# STM32H503xx register map
File version: 1.0
Registers are 32-bit, read-write, reset 0x0 unless marked. A register's access mark holds for its fields unless they carry their own. Offsets are from the block's base; [hi:lo] are bit positions; {n}, {i} and the like mark numbered series; 'fields as' and 'values as' point back to an identical list.

## RCC — Reset and Clock Control
Base 0x44020C00
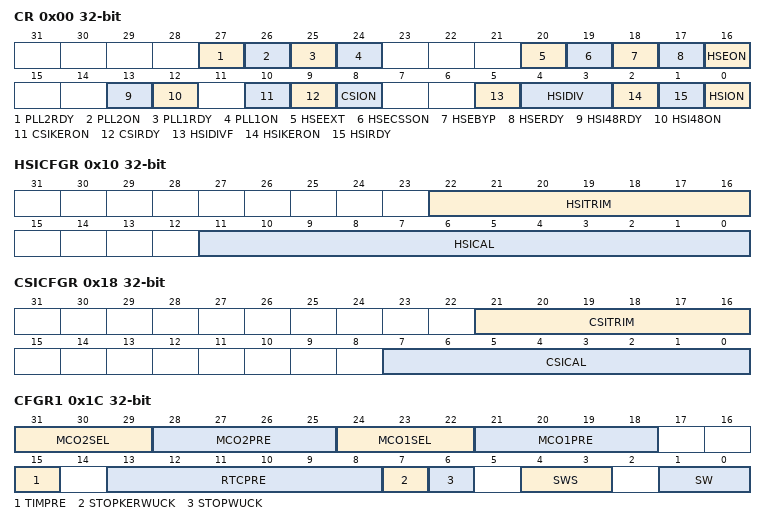
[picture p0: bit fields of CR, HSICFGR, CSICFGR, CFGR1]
0x00 CR — RCC clock control register
  [27] PLL2RDY — PLL2 ready
  [26] PLL2ON — PLL2 enable
  [25] PLL1RDY — System PLL clock ready
  [24] PLL1ON — System PLL clock enable
  [20] HSEEXT — External High Speed clock type in Bypass mode
    0=ANALOG_TYPE (ANALOG clock used as HSE external clock source); 1=DIGITAL_TYPE (DIGITAL clock used as HSE external clock source)
  [19] HSECSSON — HSE Clock Security System enable
  [18] HSEBYP — External High Speed oscillator (HSE) clock bypass
  [17] HSERDY — External High Speed oscillator (HSE) clock ready
  [16] HSEON — External High Speed oscillator (HSE) clock enable
  [13] HSI48RDY — HSI48 clock ready
  [12] HSI48ON — HSI48 clock enable
  [10] CSIKERON — The Internal RC 4MHz oscillator (CSI) clock enable for some IPs Kernel
  [9] CSIRDY — The Internal RC 4MHz oscillator (CSI) clock ready
  [8] CSION — The Internal RC 4MHz oscillator (CSI) clock enable
  [5] HSIDIVF — HSI Divider flag
  [4:3] HSIDIV — Internal High Speed clock divider selection
    0=DIV_1 (HSI_DIV1 clock activation); 1=DIV_2 (HSI_DIV2 clock activation); 2=DIV_4 (HSI_DIV4 clock activation); 3=DIV_8 (HSI_DIV8 clock activation)
  [2] HSIKERON — Internal High Speed oscillator (HSI) clock enable for some IPs Kernel
  [1] HSIRDY — Internal High Speed oscillator (HSI) clock ready flag
  [0] HSION — Internal High Speed oscillator (HSI) clock enable
0x10 HSICFGR — RCC HSI Clock Calibration Register
  [22:16] HSITRIM — HSITRIM[6:0] bits
  [11:0] HSICAL — HSICAL[11:0] bits
0x14 CRRCR — RCC Clock Recovery RC Register
  [9:0] HSI48CAL — HSI48CAL[8:0] bits
0x18 CSICFGR — RCC CSI Clock Calibration Register
  [21:16] CSITRIM — CSITRIM[5:0] bits
  [7:0] CSICAL — CSICAL[7:0] bits
0x1C CFGR1 — RCC clock configuration register 1
  [31:29] MCO2SEL
  [28:25] MCO2PRE
  [24:22] MCO1SEL
  [21:18] MCO1PRE
  [15] TIMPRE
    0=TWICE; 1=FOUR_TIMES
  [13:8] RTCPRE — HSE division factor for RTC Clock
    0=NOCLOCK; {v}=DIV_{v} (v=2..63)
  [7] STOPKERWUCK — Kernel Clock Selection after a Wake Up from STOP
    0=HSI (HSI selection as kernel clock after wake-up from STOP); 1=CSI (CSI selection as kernel clock after wake-up from STOP)
  [6] STOPWUCK — Wake Up from stop and HSE CSS backup clock selection
    0=HSI (HSI selection as system clock after wake-up from STOP); 1=CSI (CSI selection as system clock after wake-up from STOP)
  [4:3] SWS — SWS[1:0] bits (System Clock Switch Status)
    0=HSI (HSI oscillator used as system clock); 1=CSI (CSI oscillator used as system clock); 2=HSE (HSE oscillator used as system clock); 3=PLL1 (PLL1 used as system clock)
  [1:0] SW — SW[1:0] bits (System clock Switch)
    0=HSI (HSI oscillator selection as system clock); 1=CSI (CSI oscillator selection as system clock); 2=HSE (HSE oscillator selection as system clock); 3=PLL1 (PLL1 selection as system clock)
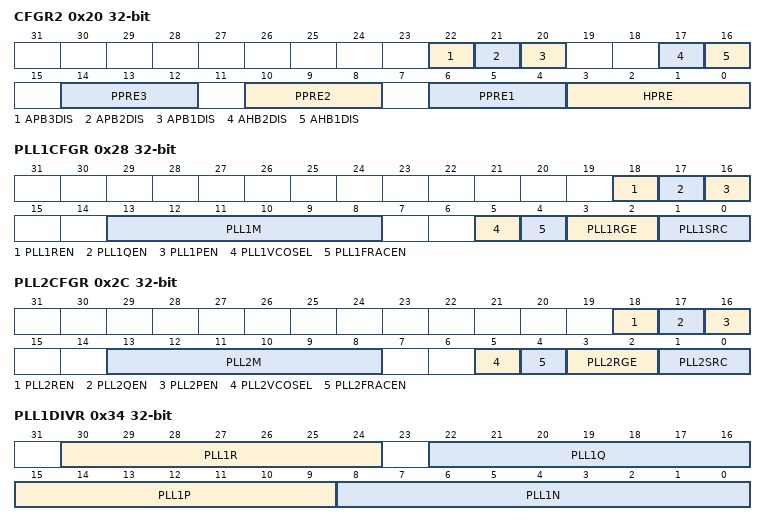
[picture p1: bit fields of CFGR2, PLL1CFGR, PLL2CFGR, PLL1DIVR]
0x20 CFGR2 — RCC clock configuration register 2
  [22] APB3DIS — APB3 clock disable
  [21] APB2DIS — APB2 clock disable
  [20] APB1DIS — APB1 clock disable
  [17] AHB2DIS — AHB2 clock disable
  [16] AHB1DIS — AHB1 clock disable
  [14:12] PPRE3 — PPRE3[2:0] bits (APB3 prescaler)
    0=DIV_1 (HCLK not divided); 4=DIV_2 (HCLK divided by 2); 5=DIV_4 (HCLK divided by 4); 6=DIV_8 (HCLK divided by 8); 7=DIV_16 (HCLK divided by 16)
  [10:8] PPRE2 — PPRE2[2:0] bits (APB2 prescaler)
    values as PPRE3
  [6:4] PPRE1 — PPRE1[2:0] bits (APB1 prescaler)
    values as PPRE3
  [3:0] HPRE — HPRE[3:0] bits (AHB prescaler)
    0=DIV_1 (SYSCLK not divided); 8=DIV_2 (SYSCLK divided by 2); 9=DIV_4 (SYSCLK divided by 4); 10=DIV_8 (SYSCLK divided by 8); 11=DIV_16 (SYSCLK divided by 16); 12=DIV_64 (SYSCLK divided by 64); 13=DIV_128 (SYSCLK divided by 128); 14=DIV_256 (SYSCLK divided by 256); 15=DIV_512 (SYSCLK divided by 512)
0x28 PLL1CFGR — RCC PLL1 Configuration Register
  [18] PLL1REN
  [17] PLL1QEN
  [16] PLL1PEN
  [13:8] PLL1M
  [5] PLL1VCOSEL
  [4] PLL1FRACEN
  [3:2] PLL1RGE
  [1:0] PLL1SRC
    0=NONE (No clock selected as main PLL1 entry clock source); 1=HSI (HSI clock selected as main PLL1 entry clock source); 2=CSI (CSI clock selected as main PLL1 entry clock source); 3=HSE (HSE clock selected as main PLL1 entry clock source)
0x2C PLL2CFGR — RCC PLL2 Configuration Register
  [18] PLL2REN
  [17] PLL2QEN
  [16] PLL2PEN
  [13:8] PLL2M
  [5] PLL2VCOSEL
  [4] PLL2FRACEN
  [3:2] PLL2RGE
  [1:0] PLL2SRC
    0=NONE (No clock selected as main PLL2 entry clock source); 2=CSI (CSI clock selected as main PLL2 entry clock source); 1=HSI (HSI clock selected as main PLL2 entry clock source); 3=HSE (HSE clock selected as main PLL2 entry clock source)
0x34 PLL1DIVR — RCC PLL1 Dividers Configuration Register
  [30:24] PLL1R, [22:16] PLL1Q, [15:9] PLL1P, [8:0] PLL1N
0x38 PLL1FRACR — RCC PLL1 Fractional Divider Configuration Register
  [15:3] PLL1FRACN
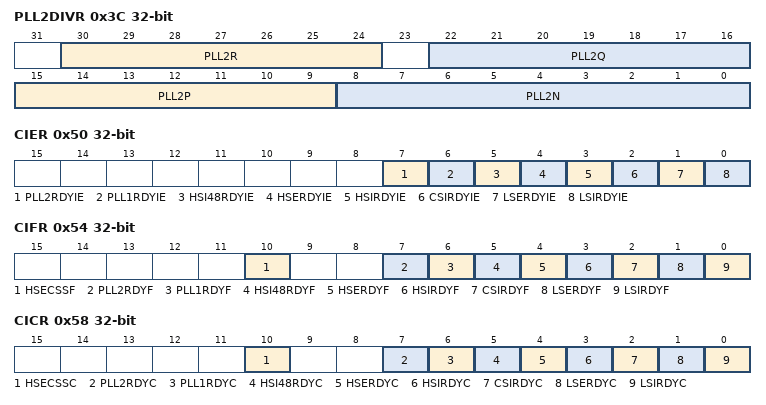
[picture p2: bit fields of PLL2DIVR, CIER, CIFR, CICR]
0x3C PLL2DIVR — RCC PLL2 Dividers Configuration Register
  [30:24] PLL2R, [22:16] PLL2Q, [15:9] PLL2P, [8:0] PLL2N
0x40 PLL2FRACR — RCC PLL2 Fractional Divider Configuration Register
  [15:3] PLL2FRACN
0x50 CIER — RCC Clock Interrupt Enable Register
  [7] PLL2RDYIE, [6] PLL1RDYIE, [5] HSI48RDYIE, [4] HSERDYIE, [3] HSIRDYIE, [2] CSIRDYIE, [1] LSERDYIE, [0] LSIRDYIE
0x54 CIFR — RCC Clock Interrupt Flag Register
  [10] HSECSSF, [7] PLL2RDYF, [6] PLL1RDYF, [5] HSI48RDYF, [4] HSERDYF, [3] HSIRDYF, [2] CSIRDYF, [1] LSERDYF, [0] LSIRDYF
0x58 CICR — RCC Clock Interrupt Clear Register
  [10] HSECSSC, [7] PLL2RDYC, [6] PLL1RDYC, [5] HSI48RDYC, [4] HSERDYC, [3] HSIRDYC, [2] CSIRDYC, [1] LSERDYC, [0] LSIRDYC
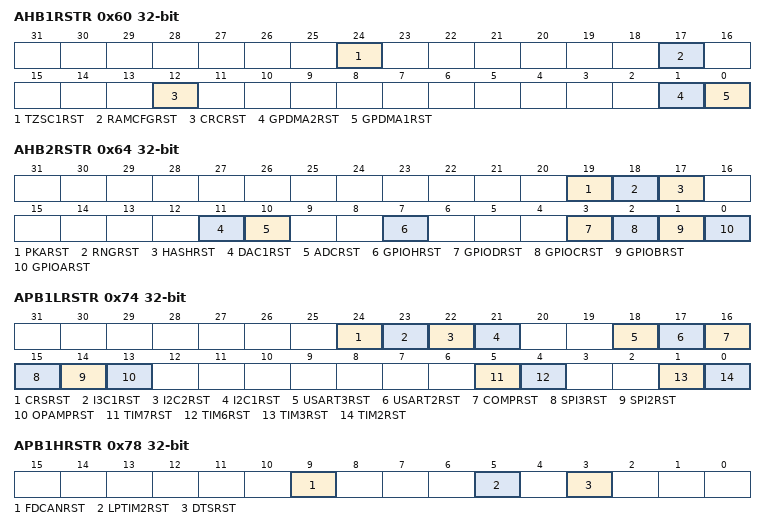
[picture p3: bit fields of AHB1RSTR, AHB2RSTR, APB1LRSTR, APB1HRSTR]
0x60 AHB1RSTR — RCC AHB1 Peripherals Reset Register
  [24] TZSC1RST, [17] RAMCFGRST, [12] CRCRST, [1] GPDMA2RST, [0] GPDMA1RST
0x64 AHB2RSTR — RCC AHB2 Peripherals Reset Register
  [19] PKARST, [18] RNGRST, [17] HASHRST, [11] DAC1RST, [10] ADCRST, [7] GPIOHRST, [3] GPIODRST, [2] GPIOCRST, [1] GPIOBRST, [0] GPIOARST
0x74 APB1LRSTR — RCC APB1 Peripherals reset Low Word register
  [24] CRSRST, [23] I3C1RST, [22] I2C2RST, [21] I2C1RST, [18] USART3RST, [17] USART2RST, [16] COMPRST, [15] SPI3RST, [14] SPI2RST, [13] OPAMPRST, [5] TIM7RST, [4] TIM6RST, [1] TIM3RST, [0] TIM2RST
0x78 APB1HRSTR — RCC APB1 Peripherals reset High Word register
  [9] FDCANRST, [5] LPTIM2RST, [3] DTSRST
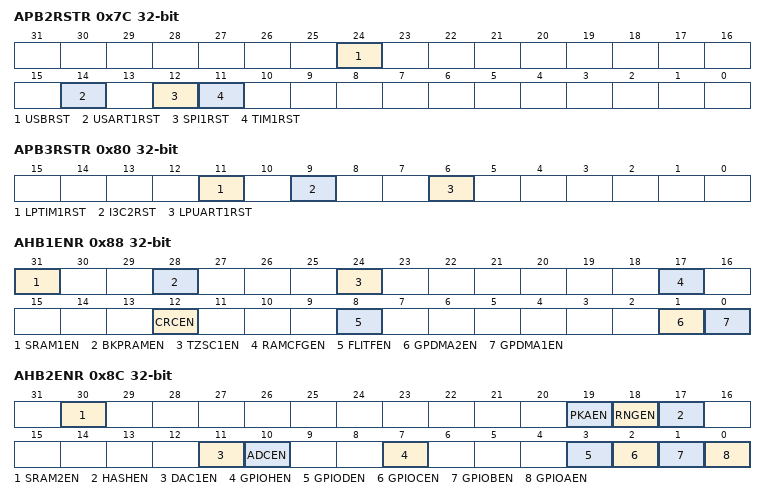
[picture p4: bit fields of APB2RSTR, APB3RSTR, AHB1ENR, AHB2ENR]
0x7C APB2RSTR — RCC APB2 Peripherals Reset Register
  [24] USBRST, [14] USART1RST, [12] SPI1RST, [11] TIM1RST
0x80 APB3RSTR — RCC APB3 Peripherals Reset Register
  [11] LPTIM1RST, [9] I3C2RST, [6] LPUART1RST
0x88 AHB1ENR — RCC AHB1 Peripherals Clock Enable Register
  [31] SRAM1EN, [28] BKPRAMEN, [24] TZSC1EN, [17] RAMCFGEN, [12] CRCEN, [8] FLITFEN, [1] GPDMA2EN, [0] GPDMA1EN
0x8C AHB2ENR — RCC AHB2 Peripherals Clock Enable Register
  [30] SRAM2EN, [19] PKAEN, [18] RNGEN, [17] HASHEN, [11] DAC1EN, [10] ADCEN, [7] GPIOHEN, [3] GPIODEN, [2] GPIOCEN, [1] GPIOBEN, [0] GPIOAEN
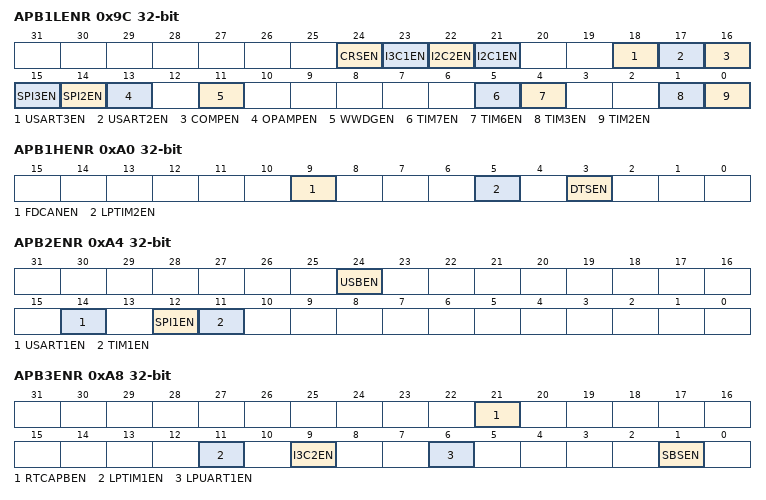
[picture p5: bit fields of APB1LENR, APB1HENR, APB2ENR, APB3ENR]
0x9C APB1LENR — RCC APB1 Peripherals clock Enable Low Word register
  [24] CRSEN, [23] I3C1EN, [22] I2C2EN, [21] I2C1EN, [18] USART3EN, [17] USART2EN, [16] COMPEN, [15] SPI3EN, [14] SPI2EN, [13] OPAMPEN, [11] WWDGEN, [5] TIM7EN, [4] TIM6EN, [1] TIM3EN, [0] TIM2EN
0xA0 APB1HENR — RCC APB1 Peripherals clock Enable High Word register
  [9] FDCANEN, [5] LPTIM2EN, [3] DTSEN
0xA4 APB2ENR — RCC APB2 Peripherals Clock Enable Register
  [24] USBEN, [14] USART1EN, [12] SPI1EN, [11] TIM1EN
0xA8 APB3ENR — RCC APB3 Peripherals Clock Enable Register
  [21] RTCAPBEN, [11] LPTIM1EN, [9] I3C2EN, [6] LPUART1EN, [1] SBSEN
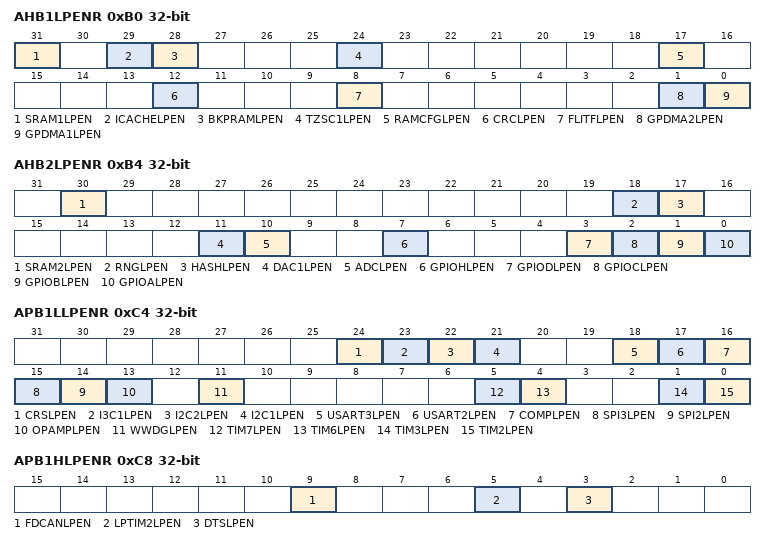
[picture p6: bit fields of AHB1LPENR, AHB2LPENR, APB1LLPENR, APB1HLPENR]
0xB0 AHB1LPENR — RCC AHB1 Peripheral sleep clock Register
  [31] SRAM1LPEN, [29] ICACHELPEN, [28] BKPRAMLPEN, [24] TZSC1LPEN, [17] RAMCFGLPEN, [12] CRCLPEN, [8] FLITFLPEN, [1] GPDMA2LPEN, [0] GPDMA1LPEN
0xB4 AHB2LPENR — RCC AHB2 Peripheral sleep clock Register
  [30] SRAM2LPEN, [18] RNGLPEN, [17] HASHLPEN, [11] DAC1LPEN, [10] ADCLPEN, [7] GPIOHLPEN, [3] GPIODLPEN, [2] GPIOCLPEN, [1] GPIOBLPEN, [0] GPIOALPEN
0xC4 APB1LLPENR — RCC APB1 Peripherals sleep clock Low Word Register
  [24] CRSLPEN, [23] I3C1LPEN, [22] I2C2LPEN, [21] I2C1LPEN, [18] USART3LPEN, [17] USART2LPEN, [16] COMPLPEN, [15] SPI3LPEN, [14] SPI2LPEN, [13] OPAMPLPEN, [11] WWDGLPEN, [5] TIM7LPEN, [4] TIM6LPEN, [1] TIM3LPEN, [0] TIM2LPEN
0xC8 APB1HLPENR — RCC APB1 Peripherals sleep clock High Word Register
  [9] FDCANLPEN, [5] LPTIM2LPEN, [3] DTSLPEN
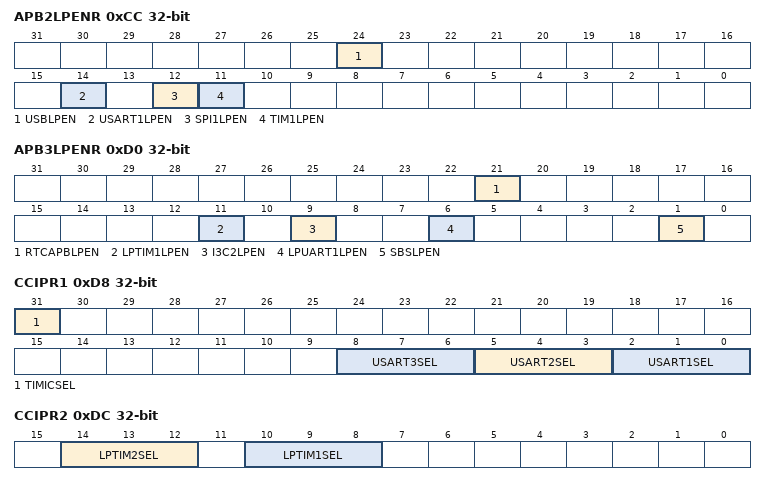
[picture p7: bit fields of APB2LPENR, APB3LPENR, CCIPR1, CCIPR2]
0xCC APB2LPENR — RCC APB2 Peripherals sleep clock Register
  [24] USBLPEN, [14] USART1LPEN, [12] SPI1LPEN, [11] TIM1LPEN
0xD0 APB3LPENR — RCC APB3 Peripherals Clock Low Power Enable Register
  [21] RTCAPBLPEN, [11] LPTIM1LPEN, [9] I3C2LPEN, [6] LPUART1LPEN, [1] SBSLPEN
0xD8 CCIPR1 — RCC IPs Clocks Configuration Register 1
  [31] TIMICSEL, [8:6] USART3SEL, [5:3] USART2SEL, [2:0] USART1SEL
0xDC CCIPR2 — RCC IPs Clocks Configuration Register 2
  [14:12] LPTIM2SEL, [10:8] LPTIM1SEL
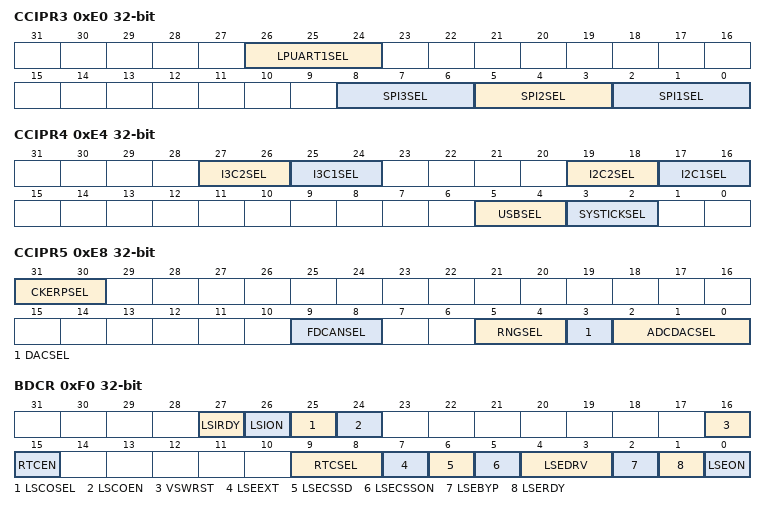
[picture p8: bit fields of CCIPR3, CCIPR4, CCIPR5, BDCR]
0xE0 CCIPR3 — RCC IPs Clocks Configuration Register 3
  [26:24] LPUART1SEL
    0=PCLK3 (PCLK3 clock used as LPUART1 clock source); 1=PLL2Q (PLL2Q clock used as LPUART1 clock source); 3=HSI (HSI clock used as LPUART1 clock source); 4=CSI (CSI clock used as LPUART1 clock source); 5=LSE (LSE clock used as LPUART1 clock source)
  [8:6] SPI3SEL
  [5:3] SPI2SEL
  [2:0] SPI1SEL
0xE4 CCIPR4 — RCC IPs Clocks Configuration Register 4
  [27:26] I3C2SEL
  [25:24] I3C1SEL
  [19:18] I2C2SEL
  [17:16] I2C1SEL
  [5:4] USBSEL
    0=NONE (No clock used as USB clock source); 1=PLL1Q (PLL1 Q clock used as USB clock source); 2=PLL2Q (PLL2 Q clock used as USB clock source); 3=HSI48 (HSI48 clock used as USB clock source)
  [3:2] SYSTICKSEL
    1=LSI (LSI clock used as SYSTICK clock source); 2=LSE (LSE clock used as SYSTICK clock source); 0=HCLKDIV8 (HCLKDIV8 clock used as SYSTICK clock source)
0xE8 CCIPR5 — RCC IPs Clocks Configuration Register 5
  [31:30] CKERPSEL
    0=HSI (HSI clock used as CLKP clock source); 1=CSI (CSI clock used as CLKP clock source); 2=HSE (HSE clock used as CLKP clock source); 3=NONE (No clock selected as CLKP clock source)
  [9:8] FDCANSEL
    0=HSE (HSE clock used as FDCAN kernel clock source); 1=PLL1Q (PLL1 Q clock used as FDCAN kernel clock source); 2=PLL2Q (PLL2 Q clock used as FDCAN kernel clock source)
  [5:4] RNGSEL
    0=HSI48 (HSI48 clock used as RNG clock source); 1=PLL1Q (PLL1 Q clock used as RNG clock source); 2=LSE (LSE clock used as RNG clock source); 3=LSI (LSI clock used as RNG clock source)
  [3] DACSEL
    0=LSE (LSE clock used as DAC low-power clock); 1=LSI (LSI clock used as DAC low-power clock)
  [2:0] ADCDACSEL
    0=HCLK (AHB clock used as ADCDAC clock source); 1=SYSCLK (SYSCLK clock used as ADCDAC clock source); 2=PLL2R (PLL2 R clock used as ADCDAC clock source); 3=HSE (HSE clock used as ADCDAC clock source); 4=HSI (HSI clock used as ADCDAC clock source); 5=CSI (CSI clock used as ADCDAC clock source)
0xF0 BDCR — RCC VSW Backup Domain & V33 Domain Control Register
  [27] LSIRDY
  [26] LSION
  [25] LSCOSEL
    0=LSI (LSI selection for low speed clock); 1=LSE (LSE selection for low speed clock)
  [24] LSCOEN
  [16] VSWRST
  [15] RTCEN
  [9:8] RTCSEL
    0=NONE (No clock used as RTC clock); 1=LSE (LSE oscillator clock used as RTC clock); 2=LSI (LSI oscillator clock used as RTC clock); 3=HSE_DIV (HSE oscillator clock divided by RTCPRE used as RTC clock)
  [7] LSEEXT
    0=ANALOG_TYPE (ANALOG clock used as LSE external clock source); 1=DIGITAL_TYPE (DIGITAL clock used as LSE external clock source)
  [6] LSECSSD
  [5] LSECSSON
  [4:3] LSEDRV
    0=LOW (Xtal mode lower driving capability); 1=MEDIUMLOW (Xtal mode medium low driving capability); 2=MEDIUMHIGH (Xtal mode medium high driving capability); 3=HIGH (Xtal mode higher driving capability)
  [2] LSEBYP
  [1] LSERDY
  [0] LSEON
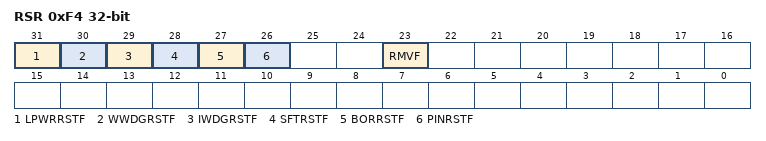
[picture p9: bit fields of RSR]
0xF4 RSR — RCC Reset status Register
  [31] LPWRRSTF, [30] WWDGRSTF, [29] IWDGRSTF, [28] SFTRSTF, [27] BORRSTF, [26] PINRSTF, [23] RMVF
0x114 PRIVCFGR — RCC Privilege configuration register
  [1] PRIV
